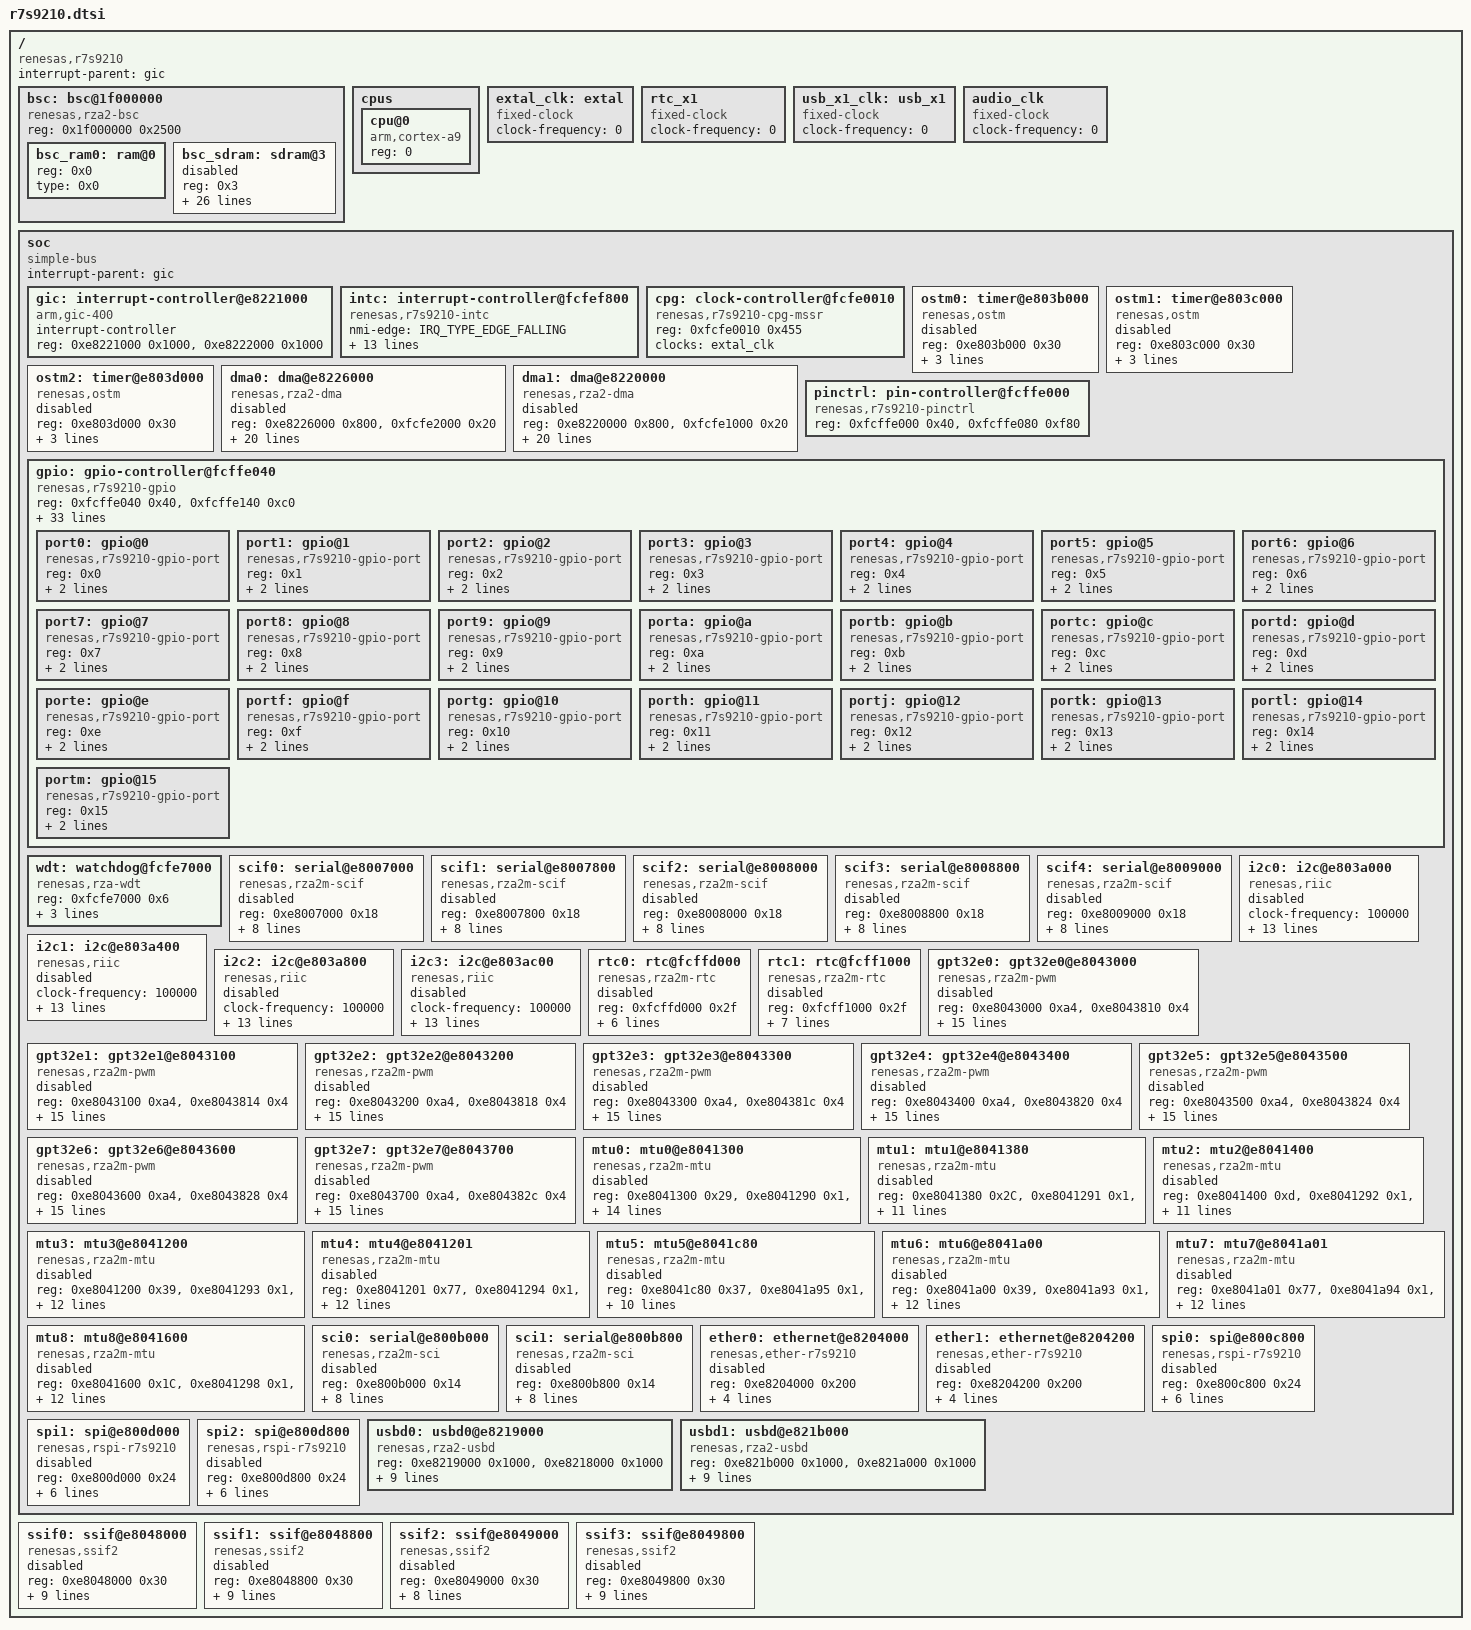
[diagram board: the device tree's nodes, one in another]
/*
 * Copyright (c) 2023 EPAM Systems
 *
 * SPDX-License-Identifier: Apache-2.0
 */

#include <mem.h>
#include <arm/armv7-a.dtsi>
#include <zephyr/dt-bindings/gpio/rza2-gpio.h>
#include <zephyr/dt-bindings/interrupt-controller/arm-gic.h>
#include <zephyr/dt-bindings/interrupt-controller/r7s9210-intc.h>
#include <zephyr/dt-bindings/clock/renesas_cpg_mssr.h>
#include <zephyr/dt-bindings/clock/r7s9210_cpg_mssr.h>
#include <zephyr/dt-bindings/dma/rza2_dma.h>
#include <zephyr/dt-bindings/pwm/pwm.h>
#include <zephyr/dt-bindings/pwm/rza2m_pwm.h>

/ {
	compatible = "renesas,r7s9210";
	interrupt-parent = <&gic>;
	#address-cells = <1>;
	#size-cells = <1>;

	bsc: bsc@1f000000 {
		compatible = "renesas,rza2-bsc";
		reg = <0x1f000000 0x2500>;
		#address-cells = <1>;
		#size-cells = <0>;

		bsc_ram0: ram@0 {
			reg = <0x0>;
			type = <0x0>; /* Normal mem */
		};

		/* Enable this node if SDRAM is connected */
		bsc_sdram: sdram@3 {
			reg = <0x3>;
			type = <0x4>; /* SDRAM */
			bsz = <16>;
			wtrp = <1>;
			wtrcd = <3>;
			a3cl = <3>;
			trwl = <2>;
			wtrc = <8>;
			auto_ref = <1>;
			bactv = <0>;
			a3row = <0x2>; /* 13 bit */
			a3col = <0x2>; /* 10 bit */
			a2row = <0x2>; /* 13 bit */
			a2col = <0x2>; /* 10 bit */
			cks = <2>; /* CKIO/16 */
			rrc = <1>;
			rtcor = <0x40>;
			sdrodly = <0x2>;
			sdridly = <0xf>;
			iwrrd = <0x0>;
			iwrrs = <0x0>;
			iww = <0x0>;
			iwrwd = <0x0>;
			iwrws = <0x0>;
			idle = <0x33F1>;
			sdcs2 = <0x0>;
			sdcs3 = <0x0>;
			status = "disabled";
		};
	};

	cpus {
		#address-cells = <1>;
		#size-cells = <0>;

		cpu@0 {
			device_type = "cpu";
			compatible = "arm,cortex-a9";
			reg = <0>;
		};
	};

	extal_clk: extal {
		#clock-cells = <0>;
		compatible = "fixed-clock";
		/* Value must be set by board */
		clock-frequency = <0>;
	};

	rtc_x1: rtc_x1 {
		#clock-cells = <0>;
		compatible = "fixed-clock";
		/* value must be set by board */
		clock-frequency = <0>;
	};

	usb_x1_clk: usb_x1 {
		#clock-cells = <0>;
		compatible = "fixed-clock";
		/* If clk present, value (48000000) must be set by board */
		clock-frequency = <0>;
	};

	audio_clk: audio_clk {
		#clock-cells = <0>;
		compatible = "fixed-clock";
		/* value must be set by board */
		clock-frequency = <0>;
	};

	soc {
		compatible = "simple-bus";
		interrupt-parent = <&gic>;

		#address-cells = <1>;
		#size-cells = <1>;
		ranges;

		gic: interrupt-controller@e8221000 {
			compatible = "arm,gic-400", "arm,gic-v2", "arm,gic";
			#interrupt-cells = <4>;
			#address-cells = <0>;
			interrupt-controller;
			reg = <0xe8221000 0x1000>,
			      <0xe8222000 0x1000>;
		};

		intc: interrupt-controller@fcfef800 {
			compatible = "renesas,r7s9210-intc";
			#interrupt-cells = <2>;
			#address-cells = <0>;
			nmi-edge = <IRQ_TYPE_EDGE_FALLING>;
			interrupts =
				<GIC_SPI 4  IRQ_TYPE_LEVEL IRQ_DEFAULT_PRIORITY>,
				<GIC_SPI 5  IRQ_TYPE_LEVEL IRQ_DEFAULT_PRIORITY>,
				<GIC_SPI 6  IRQ_TYPE_LEVEL IRQ_DEFAULT_PRIORITY>,
				<GIC_SPI 7  IRQ_TYPE_LEVEL IRQ_DEFAULT_PRIORITY>,
				<GIC_SPI 8  IRQ_TYPE_LEVEL IRQ_DEFAULT_PRIORITY>,
				<GIC_SPI 9  IRQ_TYPE_LEVEL IRQ_DEFAULT_PRIORITY>,
				<GIC_SPI 10 IRQ_TYPE_LEVEL IRQ_DEFAULT_PRIORITY>,
				<GIC_SPI 11 IRQ_TYPE_LEVEL IRQ_DEFAULT_PRIORITY>;
			map = <0 1 2 3 4 5 6 7>;
			interrupt-controller;
			interrupt-parent = <&gic>;
			reg = <0xfcfef800 0x6>;
		};

		cpg: clock-controller@fcfe0010 {
			compatible = "renesas,r7s9210-cpg-mssr";
			reg = <0xfcfe0010 0x455>;
			#clock-cells = <2>;
			clocks = <&extal_clk>;
		};

		/* By default, this timer can only be accessed from security mode. If you wish to
		 * enable access to it from non-secure mode, you will need to modify the SLVACCCTL1
		 * AXI register.
		 * See, RZ/A2M Group User’s Manual: Hardware (R01UH0746EJ0400 Rev.4.00)
		 * 5.11.26 Slave Access Control Register 1 (SLVACCCTL1)
		 */
		ostm0: timer@e803b000 {
			compatible = "renesas,ostm";
			reg = <0xe803b000 0x30>;
			interrupts = <GIC_SPI 56 IRQ_TYPE_LEVEL IRQ_DEFAULT_PRIORITY>;
			clocks = <&cpg CPG_MOD 36>;
			status = "disabled";
		};

		ostm1: timer@e803c000 {
			compatible = "renesas,ostm";
			reg = <0xe803c000 0x30>;
			interrupts = <GIC_SPI 57 IRQ_TYPE_EDGE IRQ_DEFAULT_PRIORITY>;
			clocks = <&cpg CPG_MOD 35>;
			status = "disabled";
		};

		ostm2: timer@e803d000 {
			compatible = "renesas,ostm";
			reg = <0xe803d000 0x30>;
			interrupts = <GIC_SPI 58 IRQ_TYPE_EDGE IRQ_DEFAULT_PRIORITY>;
			clocks = <&cpg CPG_MOD 34>;
			status = "disabled";
		};

		dma0: dma@e8226000 { /* Non Secure DMA */
			compatible = "renesas,rza2-dma";
			reg = <0xe8226000 0x800>, <0xfcfe2000 0x20>;
			reg-names = "reg_main", "ext";
			interrupts = <GIC_SPI 302 IRQ_TYPE_EDGE IRQ_DEFAULT_PRIORITY>,
				     <GIC_SPI 303 IRQ_TYPE_EDGE IRQ_DEFAULT_PRIORITY>,
				     <GIC_SPI 304 IRQ_TYPE_EDGE IRQ_DEFAULT_PRIORITY>,
				     <GIC_SPI 305 IRQ_TYPE_EDGE IRQ_DEFAULT_PRIORITY>,
				     <GIC_SPI 306 IRQ_TYPE_EDGE IRQ_DEFAULT_PRIORITY>,
				     <GIC_SPI 307 IRQ_TYPE_EDGE IRQ_DEFAULT_PRIORITY>,
				     <GIC_SPI 308 IRQ_TYPE_EDGE IRQ_DEFAULT_PRIORITY>,
				     <GIC_SPI 309 IRQ_TYPE_EDGE IRQ_DEFAULT_PRIORITY>,
				     <GIC_SPI 310 IRQ_TYPE_EDGE IRQ_DEFAULT_PRIORITY>,
				     <GIC_SPI 311 IRQ_TYPE_EDGE IRQ_DEFAULT_PRIORITY>,
				     <GIC_SPI 358 IRQ_TYPE_EDGE IRQ_DEFAULT_PRIORITY>,
				     <GIC_SPI 359 IRQ_TYPE_EDGE IRQ_DEFAULT_PRIORITY>,
				     <GIC_SPI 360 IRQ_TYPE_EDGE IRQ_DEFAULT_PRIORITY>,
				     <GIC_SPI 361 IRQ_TYPE_EDGE IRQ_DEFAULT_PRIORITY>,
				     <GIC_SPI 362 IRQ_TYPE_EDGE IRQ_DEFAULT_PRIORITY>,
				     <GIC_SPI 363 IRQ_TYPE_EDGE IRQ_DEFAULT_PRIORITY>,
				     <GIC_SPI 30 IRQ_TYPE_EDGE IRQ_DEFAULT_PRIORITY>; /* DMAERR1 */
			interrupt-names = "ch0", "ch1", "ch2", "ch3",
					"ch4", "ch5", "ch6", "ch7",
					"ch8", "ch9", "ch10", "ch11",
					"ch12", "ch13", "ch14", "ch15",
					"err1";
			dma-channels = <16>;
			#dma-cells = <3>;
			dma-buf-addr-alignment = <4>;
			status = "disabled";
		};

		dma1: dma@e8220000 { /* Secure DMA */
			compatible = "renesas,rza2-dma";
			reg = <0xe8220000 0x800>, <0xfcfe1000 0x20>;
			reg-names = "reg_main", "ext";
			interrupts = <GIC_SPI 13 IRQ_TYPE_EDGE IRQ_DEFAULT_PRIORITY>,
				     <GIC_SPI 14 IRQ_TYPE_EDGE IRQ_DEFAULT_PRIORITY>,
				     <GIC_SPI 15 IRQ_TYPE_EDGE IRQ_DEFAULT_PRIORITY>,
				     <GIC_SPI 16 IRQ_TYPE_EDGE IRQ_DEFAULT_PRIORITY>,
				     <GIC_SPI 17 IRQ_TYPE_EDGE IRQ_DEFAULT_PRIORITY>,
				     <GIC_SPI 18 IRQ_TYPE_EDGE IRQ_DEFAULT_PRIORITY>,
				     <GIC_SPI 19 IRQ_TYPE_EDGE IRQ_DEFAULT_PRIORITY>,
				     <GIC_SPI 20 IRQ_TYPE_EDGE IRQ_DEFAULT_PRIORITY>,
				     <GIC_SPI 21 IRQ_TYPE_EDGE IRQ_DEFAULT_PRIORITY>,
				     <GIC_SPI 22 IRQ_TYPE_EDGE IRQ_DEFAULT_PRIORITY>,
				     <GIC_SPI 23 IRQ_TYPE_EDGE IRQ_DEFAULT_PRIORITY>,
				     <GIC_SPI 24 IRQ_TYPE_EDGE IRQ_DEFAULT_PRIORITY>,
				     <GIC_SPI 25 IRQ_TYPE_EDGE IRQ_DEFAULT_PRIORITY>,
				     <GIC_SPI 26 IRQ_TYPE_EDGE IRQ_DEFAULT_PRIORITY>,
				     <GIC_SPI 27 IRQ_TYPE_EDGE IRQ_DEFAULT_PRIORITY>,
				     <GIC_SPI 28 IRQ_TYPE_EDGE IRQ_DEFAULT_PRIORITY>,
				     <GIC_SPI 29 IRQ_TYPE_EDGE IRQ_DEFAULT_PRIORITY>; /* DMAERR0 */
			interrupt-names = "ch0", "ch1", "ch2", "ch3",
					"ch4", "ch5", "ch6", "ch7",
					"ch8", "ch9", "ch10", "ch11",
					"ch12", "ch13", "ch14", "ch15",
					"err0";
			dma-channels = <16>;
			#dma-cells = <3>;
			dma-buf-addr-alignment = <4>;
			status = "disabled";
		};

		pinctrl: pin-controller@fcffe000 {
			compatible = "renesas,r7s9210-pinctrl";
			reg = <0xfcffe000 0x40>, <0xfcffe080 0xf80>;
			reg-names = "pdr", "pinctrl";
		};

		gpio: gpio-controller@fcffe040{
			compatible = "renesas,r7s9210-gpio";
			reg = <0xfcffe040 0x40>, <0xfcffe140 0xc0>;
			reg-names = "io", "dscr";
			#address-cells = <1>;
			#size-cells = <0>;

			interrupts = <GIC_SPI 479 IRQ_TYPE_EDGE IRQ_DEFAULT_PRIORITY>, /* TINT31 */
				     <GIC_SPI 478 IRQ_TYPE_EDGE IRQ_DEFAULT_PRIORITY>, /* TINT30 */
				     <GIC_SPI 477 IRQ_TYPE_EDGE IRQ_DEFAULT_PRIORITY>, /* TINT29 */
				     <GIC_SPI 476 IRQ_TYPE_EDGE IRQ_DEFAULT_PRIORITY>, /* TINT28 */
				     <GIC_SPI 475 IRQ_TYPE_EDGE IRQ_DEFAULT_PRIORITY>, /* TINT27 */
				     <GIC_SPI 474 IRQ_TYPE_EDGE IRQ_DEFAULT_PRIORITY>, /* TINT26 */
				     <GIC_SPI 473 IRQ_TYPE_EDGE IRQ_DEFAULT_PRIORITY>, /* TINT25 */
				     <GIC_SPI 472 IRQ_TYPE_EDGE IRQ_DEFAULT_PRIORITY>, /* TINT24 */
				     <GIC_SPI 471 IRQ_TYPE_EDGE IRQ_DEFAULT_PRIORITY>, /* TINT23 */
				     <GIC_SPI 470 IRQ_TYPE_EDGE IRQ_DEFAULT_PRIORITY>, /* TINT22 */
				     <GIC_SPI 469 IRQ_TYPE_EDGE IRQ_DEFAULT_PRIORITY>, /* TINT21 */
				     <GIC_SPI 468 IRQ_TYPE_EDGE IRQ_DEFAULT_PRIORITY>, /* TINT20 */
				     <GIC_SPI 467 IRQ_TYPE_EDGE IRQ_DEFAULT_PRIORITY>, /* TINT19 */
				     <GIC_SPI 466 IRQ_TYPE_EDGE IRQ_DEFAULT_PRIORITY>, /* TINT18 */
				     <GIC_SPI 465 IRQ_TYPE_EDGE IRQ_DEFAULT_PRIORITY>, /* TINT17 */
				     <GIC_SPI 464 IRQ_TYPE_EDGE IRQ_DEFAULT_PRIORITY>, /* TINT16 */
				     <GIC_SPI 463 IRQ_TYPE_EDGE IRQ_DEFAULT_PRIORITY>, /* TINT15 */
				     <GIC_SPI 462 IRQ_TYPE_EDGE IRQ_DEFAULT_PRIORITY>, /* TINT14 */
				     <GIC_SPI 461 IRQ_TYPE_EDGE IRQ_DEFAULT_PRIORITY>, /* TINT13 */
				     <GIC_SPI 460 IRQ_TYPE_EDGE IRQ_DEFAULT_PRIORITY>, /* TINT12 */
				     <GIC_SPI 459 IRQ_TYPE_EDGE IRQ_DEFAULT_PRIORITY>, /* TINT11 */
				     <GIC_SPI 458 IRQ_TYPE_EDGE IRQ_DEFAULT_PRIORITY>, /* TINT10 */
				     <GIC_SPI 457 IRQ_TYPE_EDGE IRQ_DEFAULT_PRIORITY>, /* TINT9 */
				     <GIC_SPI 456 IRQ_TYPE_EDGE IRQ_DEFAULT_PRIORITY>, /* TINT8 */
				     <GIC_SPI 455 IRQ_TYPE_EDGE IRQ_DEFAULT_PRIORITY>, /* TINT7 */
				     <GIC_SPI 454 IRQ_TYPE_EDGE IRQ_DEFAULT_PRIORITY>, /* TINT6 */
				     <GIC_SPI 453 IRQ_TYPE_EDGE IRQ_DEFAULT_PRIORITY>, /* TINT5 */
				     <GIC_SPI 452 IRQ_TYPE_EDGE IRQ_DEFAULT_PRIORITY>, /* TINT4 */
				     <GIC_SPI 451 IRQ_TYPE_EDGE IRQ_DEFAULT_PRIORITY>, /* TINT3 */
				     <GIC_SPI 450 IRQ_TYPE_EDGE IRQ_DEFAULT_PRIORITY>, /* TINT2 */
				     <GIC_SPI 449 IRQ_TYPE_EDGE IRQ_DEFAULT_PRIORITY>, /* TINT1 */
				     <GIC_SPI 448 IRQ_TYPE_EDGE IRQ_DEFAULT_PRIORITY>; /* TINT0 */

			port0: gpio@0 {
				compatible = "renesas,r7s9210-gpio-port";
				reg = <0x0>; /* PORT0 */
				gpio-controller;
				#gpio-cells=<2>;
				ngpios = <8>;
			};

			port1: gpio@1 {
				compatible = "renesas,r7s9210-gpio-port";
				reg = <0x1>; /* PORT1 */
				gpio-controller;
				#gpio-cells=<2>;
				ngpios = <8>;
			};
			port2: gpio@2 {
				compatible = "renesas,r7s9210-gpio-port";
				reg = <0x2>; /* PORT2 */
				gpio-controller;
				#gpio-cells=<2>;
				ngpios = <8>;
			};
			port3: gpio@3 {
				compatible = "renesas,r7s9210-gpio-port";
				reg = <0x3>; /* PORT3 */
				gpio-controller;
				#gpio-cells=<2>;
				ngpios = <8>;
			};
			port4: gpio@4 {
				compatible = "renesas,r7s9210-gpio-port";
				reg = <0x4>; /* PORT4 */
				gpio-controller;
				#gpio-cells=<2>;
				ngpios = <8>;
			};
			port5: gpio@5 {
				compatible = "renesas,r7s9210-gpio-port";
				reg = <0x5>; /* PORT5 */
				gpio-controller;
				#gpio-cells=<2>;
				ngpios = <8>;
			};
			port6: gpio@6 {
				compatible = "renesas,r7s9210-gpio-port";
				reg = <0x6>; /* PORT6 */
				gpio-controller;
				#gpio-cells=<2>;
				ngpios = <8>;
			};
			port7: gpio@7 {
				compatible = "renesas,r7s9210-gpio-port";
				reg = <0x7>; /* PORT7 */
				gpio-controller;
				#gpio-cells=<2>;
				ngpios = <8>;
			};
			port8: gpio@8 {
				compatible = "renesas,r7s9210-gpio-port";
				reg = <0x8>; /* PORT8 */
				gpio-controller;
				#gpio-cells=<2>;
				ngpios = <8>;
			};
			port9: gpio@9 {
				compatible = "renesas,r7s9210-gpio-port";
				reg = <0x9>; /* PORT9 */
				gpio-controller;
				#gpio-cells=<2>;
				ngpios = <8>;
			};
			porta: gpio@a {
				compatible = "renesas,r7s9210-gpio-port";
				reg = <0xa>; /* PORTA */
				gpio-controller;
				#gpio-cells=<2>;
				ngpios = <8>;
			};
			portb: gpio@b {
				compatible = "renesas,r7s9210-gpio-port";
				reg = <0xb>; /* PORTB */
				gpio-controller;
				#gpio-cells=<2>;
				ngpios = <8>;
			};
			portc: gpio@c {
				compatible = "renesas,r7s9210-gpio-port";
				reg = <0xc>; /* PORTC */
				gpio-controller;
				#gpio-cells=<2>;
				ngpios = <8>;
			};
			portd: gpio@d {
				compatible = "renesas,r7s9210-gpio-port";
				reg = <0xd>; /* PORTD */
				gpio-controller;
				#gpio-cells=<2>;
				ngpios = <8>;
			};
			porte: gpio@e {
				compatible = "renesas,r7s9210-gpio-port";
				reg = <0xe>; /* PORTE */
				gpio-controller;
				#gpio-cells=<2>;
				ngpios = <8>;
			};
			portf: gpio@f {
				compatible = "renesas,r7s9210-gpio-port";
				reg = <0xf>; /* PORTF */
				gpio-controller;
				#gpio-cells=<2>;
				ngpios = <8>;
			};
			portg: gpio@10 {
				compatible = "renesas,r7s9210-gpio-port";
				reg = <0x10>; /* PORTG */
				gpio-controller;
				#gpio-cells=<2>;
				ngpios = <8>;
			};
			porth: gpio@11 {
				compatible = "renesas,r7s9210-gpio-port";
				reg = <0x11>; /* PORTH */
				gpio-controller;
				#gpio-cells=<2>;
				ngpios = <8>;
			};
			portj: gpio@12 {
				compatible = "renesas,r7s9210-gpio-port";
				reg = <0x12>; /* PORTJ */
				gpio-controller;
				#gpio-cells=<2>;
				ngpios = <8>;
			};
			portk: gpio@13 {
				compatible = "renesas,r7s9210-gpio-port";
				reg = <0x13>; /* PORTK */
				gpio-controller;
				#gpio-cells=<2>;
				ngpios = <8>;
			};
			portl: gpio@14 {
				compatible = "renesas,r7s9210-gpio-port";
				reg = <0x14>; /* PORTL */
				gpio-controller;
				#gpio-cells=<2>;
				ngpios = <8>;
			};
			portm: gpio@15 {
				compatible = "renesas,r7s9210-gpio-port";
				reg = <0x15>; /* PORTM */
				gpio-controller;
				#gpio-cells=<2>;
				ngpios = <8>;
			};
		};

		wdt: watchdog@fcfe7000 {
			compatible = "renesas,rza-wdt";
			reg = <0xfcfe7000 0x6>;
			/* interval timer interrupt is generated only in interval timer mode */
			interrupts = <GIC_SPI 61 IRQ_TYPE_LEVEL IRQ_DEFAULT_PRIORITY>;
			clocks = <&cpg CPG_CORE R7S9210_CLK_P0>;
		};

		scif0: serial@e8007000 {
			compatible = "renesas,rza2m-scif";
			reg = <0xe8007000 0x18>;
			interrupt-parent = <&gic>;
			interrupts = <GIC_SPI 265 IRQ_TYPE_LEVEL IRQ_DEFAULT_PRIORITY>,
				     <GIC_SPI 266 IRQ_TYPE_LEVEL IRQ_DEFAULT_PRIORITY>,
				     <GIC_SPI 267 IRQ_TYPE_LEVEL IRQ_DEFAULT_PRIORITY>,
				     <GIC_SPI 268 IRQ_TYPE_LEVEL IRQ_DEFAULT_PRIORITY>;
			interrupt-names = "eri", "rxi", "txi", "tei";
			clocks = <&cpg CPG_MOD 47>, <&cpg CPG_CORE R7S9210_CLK_P1C>;
			clock-names = "fck", "bus";
			status = "disabled";
		};

		scif1: serial@e8007800 {
			compatible = "renesas,rza2m-scif";
			reg = <0xe8007800 0x18>;
			interrupt-parent = <&gic>;
			interrupts = <GIC_SPI 271 IRQ_TYPE_LEVEL IRQ_DEFAULT_PRIORITY>,
				     <GIC_SPI 272 IRQ_TYPE_LEVEL IRQ_DEFAULT_PRIORITY>,
				     <GIC_SPI 273 IRQ_TYPE_LEVEL IRQ_DEFAULT_PRIORITY>,
				     <GIC_SPI 274 IRQ_TYPE_LEVEL IRQ_DEFAULT_PRIORITY>;
			interrupt-names = "eri", "rxi", "txi", "tei";
			clocks = <&cpg CPG_MOD 46>, <&cpg CPG_CORE R7S9210_CLK_P1C>;
			clock-names = "fck", "bus";
			status = "disabled";
		};

		scif2: serial@e8008000 {
			compatible = "renesas,rza2m-scif";
			reg = <0xe8008000 0x18>;
			interrupt-parent = <&gic>;
			interrupts = <GIC_SPI 277 IRQ_TYPE_LEVEL IRQ_DEFAULT_PRIORITY>,
				     <GIC_SPI 278 IRQ_TYPE_LEVEL IRQ_DEFAULT_PRIORITY>,
				     <GIC_SPI 279 IRQ_TYPE_LEVEL IRQ_DEFAULT_PRIORITY>,
				     <GIC_SPI 280 IRQ_TYPE_LEVEL IRQ_DEFAULT_PRIORITY>;
			interrupt-names = "eri", "rxi", "txi", "tei";
			clocks = <&cpg CPG_MOD 45>, <&cpg CPG_CORE R7S9210_CLK_P1C>;
			clock-names = "fck", "bus";
			status = "disabled";
		};

		scif3: serial@e8008800 {
			compatible = "renesas,rza2m-scif";
			reg = <0xe8008800 0x18>;
			interrupt-parent = <&gic>;
			interrupts = <GIC_SPI 283 IRQ_TYPE_LEVEL IRQ_DEFAULT_PRIORITY>,
				     <GIC_SPI 284 IRQ_TYPE_LEVEL IRQ_DEFAULT_PRIORITY>,
				     <GIC_SPI 285 IRQ_TYPE_LEVEL IRQ_DEFAULT_PRIORITY>,
				     <GIC_SPI 286 IRQ_TYPE_LEVEL IRQ_DEFAULT_PRIORITY>;
			interrupt-names = "eri", "rxi", "txi", "tei";
			clocks = <&cpg CPG_MOD 44>, <&cpg CPG_CORE R7S9210_CLK_P1C>;
			clock-names = "fck", "bus";
			status = "disabled";
		};

		scif4: serial@e8009000 {
			compatible = "renesas,rza2m-scif";
			reg = <0xe8009000 0x18>;
			interrupt-parent = <&gic>;
			interrupts = <GIC_SPI 289 IRQ_TYPE_LEVEL IRQ_DEFAULT_PRIORITY>,
				     <GIC_SPI 290 IRQ_TYPE_LEVEL IRQ_DEFAULT_PRIORITY>,
				     <GIC_SPI 291 IRQ_TYPE_LEVEL IRQ_DEFAULT_PRIORITY>,
				     <GIC_SPI 292 IRQ_TYPE_LEVEL IRQ_DEFAULT_PRIORITY>;
			interrupt-names = "eri", "rxi", "txi", "tei";
			clocks = <&cpg CPG_MOD 43>, <&cpg CPG_CORE R7S9210_CLK_P1C>;
			clock-names = "fck", "bus";
			status = "disabled";
		};

		i2c0: i2c@e803a000 {
			compatible = "renesas,riic";
			clock-frequency = <100000>;
			#address-cells = <1>;
			#size-cells = <0>;
			reg = <0xe803a000 0x50>;
			interrupt-parent = <&gic>;
			interrupts = <GIC_SPI 232 IRQ_TYPE_LEVEL IRQ_DEFAULT_PRIORITY>,
				     <GIC_SPI 233 IRQ_TYPE_EDGE IRQ_DEFAULT_PRIORITY>,
				     <GIC_SPI 234 IRQ_TYPE_EDGE IRQ_DEFAULT_PRIORITY>,
				     <GIC_SPI 235 IRQ_TYPE_LEVEL IRQ_DEFAULT_PRIORITY>,
				     <GIC_SPI 236 IRQ_TYPE_LEVEL IRQ_DEFAULT_PRIORITY>,
				     <GIC_SPI 237 IRQ_TYPE_LEVEL IRQ_DEFAULT_PRIORITY>,
				     <GIC_SPI 238 IRQ_TYPE_LEVEL IRQ_DEFAULT_PRIORITY>,
				     <GIC_SPI 239 IRQ_TYPE_LEVEL IRQ_DEFAULT_PRIORITY>;
			interrupt-names = "tei", "ri", "ti", "spi",
					  "sti", "nacki", "ali", "tmoi";
			clocks = <&cpg CPG_MOD 87>, <&cpg CPG_CORE R7S9210_CLK_P1>;
			status = "disabled";
		};
		i2c1: i2c@e803a400 {
			compatible = "renesas,riic";
			clock-frequency = <100000>;
			#address-cells = <1>;
			#size-cells = <0>;
			reg = <0xe803a400 0x50>;
			interrupt-parent = <&gic>;
			interrupts = <GIC_SPI 240 IRQ_TYPE_LEVEL IRQ_DEFAULT_PRIORITY>,
				     <GIC_SPI 241 IRQ_TYPE_EDGE IRQ_DEFAULT_PRIORITY>,
				     <GIC_SPI 242 IRQ_TYPE_EDGE IRQ_DEFAULT_PRIORITY>,
				     <GIC_SPI 243 IRQ_TYPE_LEVEL IRQ_DEFAULT_PRIORITY>,
				     <GIC_SPI 244 IRQ_TYPE_LEVEL IRQ_DEFAULT_PRIORITY>,
				     <GIC_SPI 245 IRQ_TYPE_LEVEL IRQ_DEFAULT_PRIORITY>,
				     <GIC_SPI 246 IRQ_TYPE_LEVEL IRQ_DEFAULT_PRIORITY>,
				     <GIC_SPI 247 IRQ_TYPE_LEVEL IRQ_DEFAULT_PRIORITY>;
			interrupt-names = "tei", "ri", "ti", "spi",
					  "sti", "nacki", "ali", "tmoi";
			clocks = <&cpg CPG_MOD 86>, <&cpg CPG_CORE R7S9210_CLK_P1>;
			status = "disabled";
		};
		i2c2: i2c@e803a800 {
			compatible = "renesas,riic";
			clock-frequency = <100000>;
			#address-cells = <1>;
			#size-cells = <0>;
			reg = <0xe803a800 0x50>;
			interrupt-parent = <&gic>;
			interrupts = <GIC_SPI 248 IRQ_TYPE_LEVEL IRQ_DEFAULT_PRIORITY>,
				     <GIC_SPI 249 IRQ_TYPE_EDGE IRQ_DEFAULT_PRIORITY>,
				     <GIC_SPI 250 IRQ_TYPE_EDGE IRQ_DEFAULT_PRIORITY>,
				     <GIC_SPI 251 IRQ_TYPE_LEVEL IRQ_DEFAULT_PRIORITY>,
				     <GIC_SPI 252 IRQ_TYPE_LEVEL IRQ_DEFAULT_PRIORITY>,
				     <GIC_SPI 253 IRQ_TYPE_LEVEL IRQ_DEFAULT_PRIORITY>,
				     <GIC_SPI 254 IRQ_TYPE_LEVEL IRQ_DEFAULT_PRIORITY>,
				     <GIC_SPI 255 IRQ_TYPE_LEVEL IRQ_DEFAULT_PRIORITY>;
			interrupt-names = "tei", "ri", "ti", "spi",
					  "sti", "nacki", "ali", "tmoi";
			clocks = <&cpg CPG_MOD 85>, <&cpg CPG_CORE R7S9210_CLK_P1>;
			status = "disabled";
		};
		i2c3: i2c@e803ac00 {
			compatible = "renesas,riic";
			clock-frequency = <100000>;
			#address-cells = <1>;
			#size-cells = <0>;
			reg = <0xe803ac00 0x50>;
			interrupt-parent = <&gic>;
			interrupts = <GIC_SPI 256 IRQ_TYPE_LEVEL IRQ_DEFAULT_PRIORITY>,
				     <GIC_SPI 257 IRQ_TYPE_EDGE IRQ_DEFAULT_PRIORITY>,
				     <GIC_SPI 258 IRQ_TYPE_EDGE IRQ_DEFAULT_PRIORITY>,
				     <GIC_SPI 259 IRQ_TYPE_LEVEL IRQ_DEFAULT_PRIORITY>,
				     <GIC_SPI 260 IRQ_TYPE_LEVEL IRQ_DEFAULT_PRIORITY>,
				     <GIC_SPI 261 IRQ_TYPE_LEVEL IRQ_DEFAULT_PRIORITY>,
				     <GIC_SPI 262 IRQ_TYPE_LEVEL IRQ_DEFAULT_PRIORITY>,
				     <GIC_SPI 263 IRQ_TYPE_LEVEL IRQ_DEFAULT_PRIORITY>;
			interrupt-names = "tei", "ri", "ti", "spi",
					  "sti", "nacki", "ali", "tmoi";
			clocks = <&cpg CPG_MOD 84>, <&cpg CPG_CORE R7S9210_CLK_P1>;
			status = "disabled";
		};

		/* secure channel */
		rtc0: rtc@fcffd000 {
			compatible = "renesas,rza2m-rtc";
			reg = <0xfcffd000 0x2f>;
			interrupts = <GIC_SPI 327 IRQ_TYPE_EDGE IRQ_DEFAULT_PRIORITY>,
				     <GIC_SPI 328 IRQ_TYPE_EDGE IRQ_DEFAULT_PRIORITY>,
				     <GIC_SPI 329 IRQ_TYPE_EDGE IRQ_DEFAULT_PRIORITY>;
			interrupt-names = "alarm", "period", "carry";
			clocks = <&cpg CPG_MOD 53>;
			alarms-count = <1>;
			status = "disabled";
		};

		/* non-secure channel */
		rtc1: rtc@fcff1000 {
			compatible = "renesas,rza2m-rtc";
			reg = <0xfcff1000 0x2f>;
			interrupts = <GIC_SPI 330 IRQ_TYPE_EDGE IRQ_DEFAULT_PRIORITY>,
				     <GIC_SPI 331 IRQ_TYPE_EDGE IRQ_DEFAULT_PRIORITY>,
				     <GIC_SPI 332 IRQ_TYPE_EDGE IRQ_DEFAULT_PRIORITY>;
			interrupt-names = "alarm", "period", "carry";
			interrupt-parent = <&gic>;
			clocks = <&cpg CPG_MOD 52>;
			alarms-count = <1>;
			status = "disabled";
		};

		/* General Purpose PWM Timer Channels */
		gpt32e0: gpt32e0@e8043000 {
			compatible = "renesas,rza2m-pwm";
			reg = <0xe8043000 0xa4>, <0xe8043810 0x4>;
			reg-names = "GPT32E", "GTESR";
			interrupts = <GIC_SPI 107 IRQ_TYPE_EDGE IRQ_DEFAULT_PRIORITY>,
				     <GIC_SPI 108 IRQ_TYPE_EDGE IRQ_DEFAULT_PRIORITY>,
				     <GIC_SPI 109 IRQ_TYPE_EDGE IRQ_DEFAULT_PRIORITY>,
				     <GIC_SPI 110 IRQ_TYPE_EDGE IRQ_DEFAULT_PRIORITY>,
				     <GIC_SPI 114 IRQ_TYPE_EDGE IRQ_DEFAULT_PRIORITY>,
				     <GIC_SPI 115 IRQ_TYPE_EDGE IRQ_DEFAULT_PRIORITY>,
				     <GIC_SPI 116 IRQ_TYPE_EDGE IRQ_DEFAULT_PRIORITY>,
				     <GIC_SPI 117 IRQ_TYPE_EDGE IRQ_DEFAULT_PRIORITY>,
				     <GIC_SPI 118 IRQ_TYPE_EDGE IRQ_DEFAULT_PRIORITY>,
				     <GIC_SPI 119 IRQ_TYPE_EDGE IRQ_DEFAULT_PRIORITY>;
			interrupt-names = "ccmpa", "ccmpb", "cmpc", "cmpd", "cmpe", "cmpf",
					  "adtrga", "adtrgb", "ovf", "unf";
			interrupt-parent = <&gic>;
			clocks = <&cpg CPG_MOD 30>, <&cpg CPG_CORE R7S9210_CLK_P1C>;
			#pwm-cells = <3>;
			channel-id = <0>;
			status = "disabled";
		};

		gpt32e1: gpt32e1@e8043100 {
			compatible = "renesas,rza2m-pwm";
			reg = <0xe8043100 0xa4>, <0xe8043814 0x4>;
			reg-names = "GPT32E", "GTESR";
			interrupts = <GIC_SPI 120 IRQ_TYPE_EDGE IRQ_DEFAULT_PRIORITY>,
				     <GIC_SPI 121 IRQ_TYPE_EDGE IRQ_DEFAULT_PRIORITY>,
				     <GIC_SPI 122 IRQ_TYPE_EDGE IRQ_DEFAULT_PRIORITY>,
				     <GIC_SPI 123 IRQ_TYPE_EDGE IRQ_DEFAULT_PRIORITY>,
				     <GIC_SPI 127 IRQ_TYPE_EDGE IRQ_DEFAULT_PRIORITY>,
				     <GIC_SPI 128 IRQ_TYPE_EDGE IRQ_DEFAULT_PRIORITY>,
				     <GIC_SPI 129 IRQ_TYPE_EDGE IRQ_DEFAULT_PRIORITY>,
				     <GIC_SPI 130 IRQ_TYPE_EDGE IRQ_DEFAULT_PRIORITY>,
				     <GIC_SPI 131 IRQ_TYPE_EDGE IRQ_DEFAULT_PRIORITY>,
				     <GIC_SPI 132 IRQ_TYPE_EDGE IRQ_DEFAULT_PRIORITY>;
			interrupt-names = "ccmpa", "ccmpb", "cmpc", "cmpd", "cmpe", "cmpf",
					  "adtrga", "adtrgb", "ovf", "unf";
			interrupt-parent = <&gic>;
			clocks = <&cpg CPG_MOD 30>, <&cpg CPG_CORE R7S9210_CLK_P1C>;
			#pwm-cells = <3>;
			channel-id = <1>;
			status = "disabled";
		};

		gpt32e2: gpt32e2@e8043200 {
			compatible = "renesas,rza2m-pwm";
			reg = <0xe8043200 0xa4>, <0xe8043818 0x4>;
			reg-names = "GPT32E", "GTESR";
			interrupts = <GIC_SPI 133 IRQ_TYPE_EDGE IRQ_DEFAULT_PRIORITY>,
				     <GIC_SPI 134 IRQ_TYPE_EDGE IRQ_DEFAULT_PRIORITY>,
				     <GIC_SPI 135 IRQ_TYPE_EDGE IRQ_DEFAULT_PRIORITY>,
				     <GIC_SPI 136 IRQ_TYPE_EDGE IRQ_DEFAULT_PRIORITY>,
				     <GIC_SPI 140 IRQ_TYPE_EDGE IRQ_DEFAULT_PRIORITY>,
				     <GIC_SPI 141 IRQ_TYPE_EDGE IRQ_DEFAULT_PRIORITY>,
				     <GIC_SPI 142 IRQ_TYPE_EDGE IRQ_DEFAULT_PRIORITY>,
				     <GIC_SPI 143 IRQ_TYPE_EDGE IRQ_DEFAULT_PRIORITY>,
				     <GIC_SPI 144 IRQ_TYPE_EDGE IRQ_DEFAULT_PRIORITY>,
				     <GIC_SPI 145 IRQ_TYPE_EDGE IRQ_DEFAULT_PRIORITY>;
			interrupt-names = "ccmpa", "ccmpb", "cmpc", "cmpd", "cmpe", "cmpf",
					  "adtrga", "adtrgb", "ovf", "unf";
			interrupt-parent = <&gic>;
			clocks = <&cpg CPG_MOD 30>, <&cpg CPG_CORE R7S9210_CLK_P1C>;
			#pwm-cells = <3>;
			channel-id = <2>;
			status = "disabled";
		};

		gpt32e3: gpt32e3@e8043300 {
			compatible = "renesas,rza2m-pwm";
			reg = <0xe8043300 0xa4>, <0xe804381c 0x4>;
			reg-names = "GPT32E", "GTESR";
			interrupts = <GIC_SPI 146 IRQ_TYPE_EDGE IRQ_DEFAULT_PRIORITY>,
				     <GIC_SPI 147 IRQ_TYPE_EDGE IRQ_DEFAULT_PRIORITY>,
				     <GIC_SPI 148 IRQ_TYPE_EDGE IRQ_DEFAULT_PRIORITY>,
				     <GIC_SPI 149 IRQ_TYPE_EDGE IRQ_DEFAULT_PRIORITY>,
				     <GIC_SPI 153 IRQ_TYPE_EDGE IRQ_DEFAULT_PRIORITY>,
				     <GIC_SPI 154 IRQ_TYPE_EDGE IRQ_DEFAULT_PRIORITY>,
				     <GIC_SPI 155 IRQ_TYPE_EDGE IRQ_DEFAULT_PRIORITY>,
				     <GIC_SPI 156 IRQ_TYPE_EDGE IRQ_DEFAULT_PRIORITY>,
				     <GIC_SPI 157 IRQ_TYPE_EDGE IRQ_DEFAULT_PRIORITY>,
				     <GIC_SPI 158 IRQ_TYPE_EDGE IRQ_DEFAULT_PRIORITY>;
			interrupt-names = "ccmpa", "ccmpb", "cmpc", "cmpd", "cmpe", "cmpf",
					  "adtrga", "adtrgb", "ovf", "unf";
			interrupt-parent = <&gic>;
			clocks = <&cpg CPG_MOD 30>, <&cpg CPG_CORE R7S9210_CLK_P1C>;
			#pwm-cells = <3>;
			channel-id = <3>;
			status = "disabled";
		};

		gpt32e4: gpt32e4@e8043400 {
			compatible = "renesas,rza2m-pwm";
			reg = <0xe8043400 0xa4>, <0xe8043820 0x4>;
			reg-names = "GPT32E", "GTESR";
			interrupts = <GIC_SPI 159 IRQ_TYPE_EDGE IRQ_DEFAULT_PRIORITY>,
				     <GIC_SPI 160 IRQ_TYPE_EDGE IRQ_DEFAULT_PRIORITY>,
				     <GIC_SPI 161 IRQ_TYPE_EDGE IRQ_DEFAULT_PRIORITY>,
				     <GIC_SPI 162 IRQ_TYPE_EDGE IRQ_DEFAULT_PRIORITY>,
				     <GIC_SPI 166 IRQ_TYPE_EDGE IRQ_DEFAULT_PRIORITY>,
				     <GIC_SPI 167 IRQ_TYPE_EDGE IRQ_DEFAULT_PRIORITY>,
				     <GIC_SPI 168 IRQ_TYPE_EDGE IRQ_DEFAULT_PRIORITY>,
				     <GIC_SPI 169 IRQ_TYPE_EDGE IRQ_DEFAULT_PRIORITY>,
				     <GIC_SPI 170 IRQ_TYPE_EDGE IRQ_DEFAULT_PRIORITY>,
				     <GIC_SPI 171 IRQ_TYPE_EDGE IRQ_DEFAULT_PRIORITY>;
			interrupt-names = "ccmpa", "ccmpb", "cmpc", "cmpd", "cmpe", "cmpf",
					  "adtrga", "adtrgb", "ovf", "unf";
			interrupt-parent = <&gic>;
			clocks = <&cpg CPG_MOD 30>, <&cpg CPG_CORE R7S9210_CLK_P1C>;
			#pwm-cells = <3>;
			channel-id = <4>;
			status = "disabled";
		};

		gpt32e5: gpt32e5@e8043500 {
			compatible = "renesas,rza2m-pwm";
			reg = <0xe8043500 0xa4>, <0xe8043824 0x4>;
			reg-names = "GPT32E", "GTESR";
			interrupts = <GIC_SPI 172 IRQ_TYPE_EDGE IRQ_DEFAULT_PRIORITY>,
				     <GIC_SPI 173 IRQ_TYPE_EDGE IRQ_DEFAULT_PRIORITY>,
				     <GIC_SPI 174 IRQ_TYPE_EDGE IRQ_DEFAULT_PRIORITY>,
				     <GIC_SPI 175 IRQ_TYPE_EDGE IRQ_DEFAULT_PRIORITY>,
				     <GIC_SPI 179 IRQ_TYPE_EDGE IRQ_DEFAULT_PRIORITY>,
				     <GIC_SPI 180 IRQ_TYPE_EDGE IRQ_DEFAULT_PRIORITY>,
				     <GIC_SPI 181 IRQ_TYPE_EDGE IRQ_DEFAULT_PRIORITY>,
				     <GIC_SPI 182 IRQ_TYPE_EDGE IRQ_DEFAULT_PRIORITY>,
				     <GIC_SPI 183 IRQ_TYPE_EDGE IRQ_DEFAULT_PRIORITY>,
				     <GIC_SPI 184 IRQ_TYPE_EDGE IRQ_DEFAULT_PRIORITY>;
			interrupt-names = "ccmpa", "ccmpb", "cmpc", "cmpd", "cmpe", "cmpf",
					  "adtrga", "adtrgb", "ovf", "unf";
			interrupt-parent = <&gic>;
			clocks = <&cpg CPG_MOD 30>, <&cpg CPG_CORE R7S9210_CLK_P1C>;
			#pwm-cells = <3>;
			channel-id = <5>;
			status = "disabled";
		};

		gpt32e6: gpt32e6@e8043600 {
			compatible = "renesas,rza2m-pwm";
			reg = <0xe8043600 0xa4>, <0xe8043828 0x4>;
			reg-names = "GPT32E", "GTESR";
			interrupts = <GIC_SPI 185 IRQ_TYPE_EDGE IRQ_DEFAULT_PRIORITY>,
				     <GIC_SPI 186 IRQ_TYPE_EDGE IRQ_DEFAULT_PRIORITY>,
				     <GIC_SPI 187 IRQ_TYPE_EDGE IRQ_DEFAULT_PRIORITY>,
				     <GIC_SPI 188 IRQ_TYPE_EDGE IRQ_DEFAULT_PRIORITY>,
				     <GIC_SPI 192 IRQ_TYPE_EDGE IRQ_DEFAULT_PRIORITY>,
				     <GIC_SPI 193 IRQ_TYPE_EDGE IRQ_DEFAULT_PRIORITY>,
				     <GIC_SPI 194 IRQ_TYPE_EDGE IRQ_DEFAULT_PRIORITY>,
				     <GIC_SPI 195 IRQ_TYPE_EDGE IRQ_DEFAULT_PRIORITY>,
				     <GIC_SPI 196 IRQ_TYPE_EDGE IRQ_DEFAULT_PRIORITY>,
				     <GIC_SPI 197 IRQ_TYPE_EDGE IRQ_DEFAULT_PRIORITY>;
			interrupt-names = "ccmpa", "ccmpb", "cmpc", "cmpd", "cmpe", "cmpf",
					  "adtrga", "adtrgb", "ovf", "unf";
			interrupt-parent = <&gic>;
			clocks = <&cpg CPG_MOD 30>, <&cpg CPG_CORE R7S9210_CLK_P1C>;
			#pwm-cells = <3>;
			channel-id = <6>;
			status = "disabled";
		};

		gpt32e7: gpt32e7@e8043700 {
			compatible = "renesas,rza2m-pwm";
			reg = <0xe8043700 0xa4>, <0xe804382c 0x4>;
			reg-names = "GPT32E", "GTESR";
			interrupts = <GIC_SPI 198 IRQ_TYPE_EDGE IRQ_DEFAULT_PRIORITY>,
				     <GIC_SPI 199 IRQ_TYPE_EDGE IRQ_DEFAULT_PRIORITY>,
				     <GIC_SPI 200 IRQ_TYPE_EDGE IRQ_DEFAULT_PRIORITY>,
				     <GIC_SPI 201 IRQ_TYPE_EDGE IRQ_DEFAULT_PRIORITY>,
				     <GIC_SPI 205 IRQ_TYPE_EDGE IRQ_DEFAULT_PRIORITY>,
				     <GIC_SPI 206 IRQ_TYPE_EDGE IRQ_DEFAULT_PRIORITY>,
				     <GIC_SPI 207 IRQ_TYPE_EDGE IRQ_DEFAULT_PRIORITY>,
				     <GIC_SPI 208 IRQ_TYPE_EDGE IRQ_DEFAULT_PRIORITY>,
				     <GIC_SPI 209 IRQ_TYPE_EDGE IRQ_DEFAULT_PRIORITY>,
				     <GIC_SPI 210 IRQ_TYPE_EDGE IRQ_DEFAULT_PRIORITY>;
			interrupt-names = "ccmpa", "ccmpb", "cmpc", "cmpd", "cmpe", "cmpf",
					  "adtrga", "adtrgb", "ovf", "unf";
			interrupt-parent = <&gic>;
			clocks = <&cpg CPG_MOD 30>, <&cpg CPG_CORE R7S9210_CLK_P1C>;
			#pwm-cells = <3>;
			channel-id = <7>;
			status = "disabled";
		};

		/* Multi-function timers (MTU) */
		mtu0: mtu0@e8041300 {
			compatible = "renesas,rza2m-mtu";
			reg = <0xe8041300 0x29>, <0xe8041290 0x1>,
			      <0xe8041299 0x1>, <0xe804120a 0x78>, <0xe8041a0a 0x7b>;
			reg-names = "mtu", "noise_flt_cr",
				    "noise_flt_cr_cmn", "mtu_cmn_a", "mtu_cmn_b";
			interrupts = <GIC_SPI 63 IRQ_TYPE_EDGE IRQ_DEFAULT_PRIORITY>,
				     <GIC_SPI 64 IRQ_TYPE_EDGE IRQ_DEFAULT_PRIORITY>,
				     <GIC_SPI 65 IRQ_TYPE_EDGE IRQ_DEFAULT_PRIORITY>,
				     <GIC_SPI 66 IRQ_TYPE_EDGE IRQ_DEFAULT_PRIORITY>,
				     <GIC_SPI 67 IRQ_TYPE_EDGE IRQ_DEFAULT_PRIORITY>,
				     <GIC_SPI 68 IRQ_TYPE_EDGE IRQ_DEFAULT_PRIORITY>,
				     <GIC_SPI 69 IRQ_TYPE_EDGE IRQ_DEFAULT_PRIORITY>;
			interrupt-names = "tgia", "tgib", "tgic", "tgid", "tciv", "tgie", "tgif";
			interrupt-parent = <&gic>;
			clocks = <&cpg CPG_MOD 33>, <&cpg CPG_CORE R7S9210_CLK_P1C>;
			#pwm-cells = <3>;
			channel-id = <0>;
			status = "disabled";
		};

		mtu1: mtu1@e8041380 {
			compatible = "renesas,rza2m-mtu";
			reg = <0xe8041380 0x2C>, <0xe8041291 0x1>,
			      <0xe8041299 0x1>, <0xe804120a 0x78>, <0xe8041a0a 0x7b>;
			reg-names = "mtu", "noise_flt_cr",
				    "noise_flt_cr_cmn", "mtu_cmn_a", "mtu_cmn_b";
			interrupts = <GIC_SPI 70 IRQ_TYPE_EDGE IRQ_DEFAULT_PRIORITY>,
				     <GIC_SPI 71 IRQ_TYPE_EDGE IRQ_DEFAULT_PRIORITY>,
				     <GIC_SPI 72 IRQ_TYPE_EDGE IRQ_DEFAULT_PRIORITY>,
				     <GIC_SPI 73 IRQ_TYPE_EDGE IRQ_DEFAULT_PRIORITY>;
			interrupt-names = "tgia", "tgib", "tciv", "tciu";
			interrupt-parent = <&gic>;
			clocks = <&cpg CPG_MOD 33>, <&cpg CPG_CORE R7S9210_CLK_P1C>;
			#pwm-cells = <3>;
			channel-id = <1>;
			status = "disabled";
		};

		mtu2: mtu2@e8041400 {
			compatible = "renesas,rza2m-mtu";
			reg = <0xe8041400 0xd>, <0xe8041292 0x1>,
			      <0xe8041299 0x1>, <0xe804120a 0x78>, <0xe8041a0a 0x7b>;
			reg-names = "mtu", "noise_flt_cr",
				    "noise_flt_cr_cmn", "mtu_cmn_a", "mtu_cmn_b";
			interrupts = <GIC_SPI 74 IRQ_TYPE_EDGE IRQ_DEFAULT_PRIORITY>,
				     <GIC_SPI 75 IRQ_TYPE_EDGE IRQ_DEFAULT_PRIORITY>,
				     <GIC_SPI 76 IRQ_TYPE_EDGE IRQ_DEFAULT_PRIORITY>,
				     <GIC_SPI 77 IRQ_TYPE_EDGE IRQ_DEFAULT_PRIORITY>;
			interrupt-names = "tgia", "tgib", "tciv", "tciu";
			interrupt-parent = <&gic>;
			clocks = <&cpg CPG_MOD 33>, <&cpg CPG_CORE R7S9210_CLK_P1C>;
			#pwm-cells = <3>;
			channel-id = <2>;
			status = "disabled";
		};

		mtu3: mtu3@e8041200 {
			compatible = "renesas,rza2m-mtu";
			reg = <0xe8041200 0x39>, <0xe8041293 0x1>,
			      <0xe8041299 0x1>, <0xe804120a 0x78>, <0xe8041a0a 0x7b>;
			reg-names = "mtu", "noise_flt_cr",
				    "noise_flt_cr_cmn", "mtu_cmn_a", "mtu_cmn_b";
			interrupts = <GIC_SPI 78 IRQ_TYPE_EDGE IRQ_DEFAULT_PRIORITY>,
				     <GIC_SPI 79 IRQ_TYPE_EDGE IRQ_DEFAULT_PRIORITY>,
				     <GIC_SPI 80 IRQ_TYPE_EDGE IRQ_DEFAULT_PRIORITY>,
				     <GIC_SPI 81 IRQ_TYPE_EDGE IRQ_DEFAULT_PRIORITY>,
				     <GIC_SPI 82 IRQ_TYPE_EDGE IRQ_DEFAULT_PRIORITY>;
			interrupt-names = "tgia", "tgib", "tgic", "tgid", "tciv";
			interrupt-parent = <&gic>;
			clocks = <&cpg CPG_MOD 33>, <&cpg CPG_CORE R7S9210_CLK_P1C>;
			#pwm-cells = <3>;
			channel-id = <3>;
			status = "disabled";
		};

		mtu4: mtu4@e8041201 {
			compatible = "renesas,rza2m-mtu";
			reg = <0xe8041201 0x77>, <0xe8041294 0x1>,
			      <0xe8041299 0x1>, <0xe804120a 0x78>, <0xe8041a0a 0x7b>;
			reg-names = "mtu", "noise_flt_cr",
				    "noise_flt_cr_cmn", "mtu_cmn_a", "mtu_cmn_b";
			interrupts = <GIC_SPI 83 IRQ_TYPE_EDGE IRQ_DEFAULT_PRIORITY>,
				     <GIC_SPI 84 IRQ_TYPE_EDGE IRQ_DEFAULT_PRIORITY>,
				     <GIC_SPI 85 IRQ_TYPE_EDGE IRQ_DEFAULT_PRIORITY>,
				     <GIC_SPI 86 IRQ_TYPE_EDGE IRQ_DEFAULT_PRIORITY>,
				     <GIC_SPI 87 IRQ_TYPE_EDGE IRQ_DEFAULT_PRIORITY>;
			interrupt-names = "tgia", "tgib", "tgic", "tgid", "tciv";
			interrupt-parent = <&gic>;
			clocks = <&cpg CPG_MOD 33>, <&cpg CPG_CORE R7S9210_CLK_P1C>;
			#pwm-cells = <3>;
			channel-id = <4>;
			status = "disabled";
		};

		mtu5: mtu5@e8041c80 {
			compatible = "renesas,rza2m-mtu";
			reg = <0xe8041c80 0x37>, <0xe8041a95 0x1>,
			      <0xe8041299 0x1>, <0xe804120a 0x78>, <0xe8041a0a 0x7b>;
			reg-names = "mtu", "noise_flt_cr",
				    "noise_flt_cr_cmn", "mtu_cmn_a", "mtu_cmn_b";
			interrupts = <GIC_SPI 88 IRQ_TYPE_EDGE IRQ_DEFAULT_PRIORITY>,
				     <GIC_SPI 89 IRQ_TYPE_EDGE IRQ_DEFAULT_PRIORITY>,
				     <GIC_SPI 90 IRQ_TYPE_EDGE IRQ_DEFAULT_PRIORITY>;
			interrupt-names = "tgiu", "tgiv", "tgiw";
			interrupt-parent = <&gic>;
			clocks = <&cpg CPG_MOD 33>, <&cpg CPG_CORE R7S9210_CLK_P1C>;
			#pwm-cells = <3>;
			channel-id = <5>;
			status = "disabled";
		};

		mtu6: mtu6@e8041a00 {
			compatible = "renesas,rza2m-mtu";
			reg = <0xe8041a00 0x39>, <0xe8041a93 0x1>,
			      <0xe8041299 0x1>, <0xe804120a 0x78>, <0xe8041a0a 0x7b>;
			reg-names = "mtu", "noise_flt_cr",
				    "noise_flt_cr_cmn", "mtu_cmn_a", "mtu_cmn_b";
			interrupts = <GIC_SPI 91 IRQ_TYPE_EDGE IRQ_DEFAULT_PRIORITY>,
				     <GIC_SPI 92 IRQ_TYPE_EDGE IRQ_DEFAULT_PRIORITY>,
				     <GIC_SPI 93 IRQ_TYPE_EDGE IRQ_DEFAULT_PRIORITY>,
				     <GIC_SPI 94 IRQ_TYPE_EDGE IRQ_DEFAULT_PRIORITY>,
				     <GIC_SPI 95 IRQ_TYPE_EDGE IRQ_DEFAULT_PRIORITY>;
			interrupt-names = "tgia", "tgib", "tgic", "tgid", "tciv";
			interrupt-parent = <&gic>;
			clocks = <&cpg CPG_MOD 33>, <&cpg CPG_CORE R7S9210_CLK_P1C>;
			#pwm-cells = <3>;
			channel-id = <6>;
			status = "disabled";
		};

		mtu7: mtu7@e8041a01 {
			compatible = "renesas,rza2m-mtu";
			reg = <0xe8041a01 0x77>, <0xe8041a94 0x1>,
			      <0xe8041299 0x1>, <0xe804120a 0x78>, <0xe8041a0a 0x7b>;
			reg-names = "mtu", "noise_flt_cr",
				    "noise_flt_cr_cmn", "mtu_cmn_a", "mtu_cmn_b";
			interrupts = <GIC_SPI 96  IRQ_TYPE_EDGE IRQ_DEFAULT_PRIORITY>,
				     <GIC_SPI 97  IRQ_TYPE_EDGE IRQ_DEFAULT_PRIORITY>,
				     <GIC_SPI 98  IRQ_TYPE_EDGE IRQ_DEFAULT_PRIORITY>,
				     <GIC_SPI 99  IRQ_TYPE_EDGE IRQ_DEFAULT_PRIORITY>,
				     <GIC_SPI 100 IRQ_TYPE_EDGE IRQ_DEFAULT_PRIORITY>;
			interrupt-names = "tgia", "tgib", "tgic", "tgid", "tciv";
			interrupt-parent = <&gic>;
			clocks = <&cpg CPG_MOD 33>, <&cpg CPG_CORE R7S9210_CLK_P1C>;
			#pwm-cells = <3>;
			channel-id = <7>;
			status = "disabled";
		};

		mtu8: mtu8@e8041600 {
			compatible = "renesas,rza2m-mtu";
			reg = <0xe8041600 0x1C>, <0xe8041298 0x1>,
			      <0xe8041299 0x1>, <0xe804120a 0x78>, <0xe8041a0a 0x7b>;
			reg-names = "mtu", "noise_flt_cr",
				    "noise_flt_cr_cmn", "mtu_cmn_a", "mtu_cmn_b";
			interrupts = <GIC_SPI 101 IRQ_TYPE_EDGE IRQ_DEFAULT_PRIORITY>,
				     <GIC_SPI 102 IRQ_TYPE_EDGE IRQ_DEFAULT_PRIORITY>,
				     <GIC_SPI 103 IRQ_TYPE_EDGE IRQ_DEFAULT_PRIORITY>,
				     <GIC_SPI 104 IRQ_TYPE_EDGE IRQ_DEFAULT_PRIORITY>,
				     <GIC_SPI 105 IRQ_TYPE_EDGE IRQ_DEFAULT_PRIORITY>;
			interrupt-names = "tgia", "tgib", "tgic", "tgid", "tciv";
			interrupt-parent = <&gic>;
			clocks = <&cpg CPG_MOD 33>, <&cpg CPG_CORE R7S9210_CLK_P1C>;
			#pwm-cells = <3>;
			channel-id = <8>;
			status = "disabled";
		};

		sci0: serial@e800b000 {
			compatible = "renesas,rza2m-sci";
			reg = <0xe800b000 0x14>;
			interrupt-parent = <&gic>;
			interrupts = <GIC_SPI 333 IRQ_TYPE_LEVEL IRQ_DEFAULT_PRIORITY>,
				     <GIC_SPI 334 IRQ_TYPE_EDGE IRQ_DEFAULT_PRIORITY>,
				     <GIC_SPI 335 IRQ_TYPE_EDGE IRQ_DEFAULT_PRIORITY>,
				     <GIC_SPI 336 IRQ_TYPE_LEVEL IRQ_DEFAULT_PRIORITY>;
			interrupt-names = "eri", "rxi", "txi", "tei";
			clocks = <&cpg CPG_MOD 42>, <&cpg CPG_CORE R7S9210_CLK_P1C>;
			clock-names = "fck", "bus";
			status = "disabled";
		};

		sci1: serial@e800b800 {
			compatible = "renesas,rza2m-sci";
			reg = <0xe800b800 0x14>;
			interrupt-parent = <&gic>;
			interrupts = <GIC_SPI 337 IRQ_TYPE_LEVEL IRQ_DEFAULT_PRIORITY>,
				     <GIC_SPI 338 IRQ_TYPE_EDGE IRQ_DEFAULT_PRIORITY>,
				     <GIC_SPI 339 IRQ_TYPE_EDGE IRQ_DEFAULT_PRIORITY>,
				     <GIC_SPI 340 IRQ_TYPE_LEVEL IRQ_DEFAULT_PRIORITY>;
			interrupt-names = "eri", "rxi", "txi", "tei";
			clocks = <&cpg CPG_MOD 41>, <&cpg CPG_CORE R7S9210_CLK_P1C>;
			clock-names = "fck", "bus";
			status = "disabled";
		};

		ether0: ethernet@e8204000 {
			compatible = "renesas,ether-r7s9210";
			reg = <0xe8204000 0x200>;
			interrupts = <GIC_SPI 341 IRQ_TYPE_LEVEL IRQ_DEFAULT_PRIORITY>;
			clocks = <&cpg CPG_MOD 65>, <&cpg CPG_MOD 62>;

			phy-mode = "rmii";
			status = "disabled";
		};

		ether1: ethernet@e8204200 {
			compatible = "renesas,ether-r7s9210";
			reg = <0xe8204200 0x200>;
			interrupts = <GIC_SPI 342 IRQ_TYPE_LEVEL IRQ_DEFAULT_PRIORITY>;
			clocks = <&cpg CPG_MOD 64>, <&cpg CPG_MOD 62>;

			phy-mode = "rmii";
			status = "disabled";
		};

		spi0: spi@e800c800 {
			compatible = "renesas,rspi-r7s9210", "renesas,rspi-rz";
			reg = <0xe800c800 0x24>;
			interrupts = <GIC_SPI 312 IRQ_TYPE_LEVEL IRQ_DEFAULT_PRIORITY>,
				     <GIC_SPI 313 IRQ_TYPE_LEVEL IRQ_DEFAULT_PRIORITY>,
				     <GIC_SPI 314 IRQ_TYPE_LEVEL IRQ_DEFAULT_PRIORITY>;
			interrupt-names = "error", "rx", "tx";
			clocks = <&cpg CPG_MOD 97>;
			num-cs = <1>;
			#address-cells = <1>;
			#size-cells = <0>;
			status = "disabled";
		};

		spi1: spi@e800d000 {
			compatible = "renesas,rspi-r7s9210", "renesas,rspi-rz";
			reg = <0xe800d000 0x24>;
			interrupts = <GIC_SPI 315 IRQ_TYPE_LEVEL IRQ_DEFAULT_PRIORITY>,
				     <GIC_SPI 316 IRQ_TYPE_LEVEL IRQ_DEFAULT_PRIORITY>,
				     <GIC_SPI 317 IRQ_TYPE_LEVEL IRQ_DEFAULT_PRIORITY>;
			interrupt-names = "error", "rx", "tx";
			clocks = <&cpg CPG_MOD 96>;
			num-cs = <1>;
			#address-cells = <1>;
			#size-cells = <0>;
			status = "disabled";
		};

		spi2: spi@e800d800 {
			compatible = "renesas,rspi-r7s9210", "renesas,rspi-rz";
			reg = <0xe800d800 0x24>;
			interrupts = <GIC_SPI 318 IRQ_TYPE_LEVEL IRQ_DEFAULT_PRIORITY>,
				     <GIC_SPI 319 IRQ_TYPE_LEVEL IRQ_DEFAULT_PRIORITY>,
				     <GIC_SPI 320 IRQ_TYPE_LEVEL IRQ_DEFAULT_PRIORITY>;
			interrupt-names = "error", "rx", "tx";
			clocks = <&cpg CPG_MOD 95>;
			num-cs = <1>;
			#address-cells = <1>;
			#size-cells = <0>;
			status = "disabled";
		};

		usbd0: usbd0@e8219000 {
			compatible = "renesas,rza2-usbd";
			reg = <0xe8219000 0x1000>, <0xe8218000 0x1000>;
			reg-names = "dev_reg", "host_reg";
			num-bidir-endpoints = <8>;
			maximum-speed = "high-speed";
			clocks = <&cpg CPG_MOD 61>, <&usb_x1_clk>;
			clock-names = "default", "usb_x1";
			interrupts = <GIC_SPI 31 IRQ_TYPE_LEVEL IRQ_DEFAULT_PRIORITY>,
				     <GIC_SPI 32 IRQ_TYPE_LEVEL IRQ_DEFAULT_PRIORITY>,
				     <GIC_SPI 33 IRQ_TYPE_LEVEL IRQ_DEFAULT_PRIORITY>,
				     <GIC_SPI 34 IRQ_TYPE_LEVEL IRQ_DEFAULT_PRIORITY>,
				     <GIC_SPI 35 IRQ_TYPE_LEVEL IRQ_DEFAULT_PRIORITY>;
			interrupt-names = "usbh", "usbf", "dma0", "dma1", "dmaerr";
		};

		usbd1: usbd@e821b000 {
			compatible = "renesas,rza2-usbd";
			reg = <0xe821b000 0x1000>, <0xe821a000 0x1000>;
			reg-names = "dev_reg", "host_reg";
			num-bidir-endpoints = <8>;
			maximum-speed = "high-speed";
			clocks = <&cpg CPG_MOD 60>, <&usb_x1_clk>;
			clock-names = "default", "usb_x1";
			interrupts = <GIC_SPI 36 IRQ_TYPE_LEVEL IRQ_DEFAULT_PRIORITY>,
				     <GIC_SPI 37 IRQ_TYPE_LEVEL IRQ_DEFAULT_PRIORITY>,
				     <GIC_SPI 38 IRQ_TYPE_LEVEL IRQ_DEFAULT_PRIORITY>,
				     <GIC_SPI 39 IRQ_TYPE_LEVEL IRQ_DEFAULT_PRIORITY>,
				     <GIC_SPI 40 IRQ_TYPE_LEVEL IRQ_DEFAULT_PRIORITY>;
			interrupt-names = "usbh", "usbf", "dma0", "dma1", "dmaerr";
		};
	};

		/* I2S Interfaces */
		ssif0: ssif@e8048000 {
			compatible = "renesas,ssif2", "renesas,rza2m-ssif2";
			#address-cells = <1>;
			#size-cells = <0>;
			reg = <0xe8048000 0x30>;
			interrupt-parent = <&gic>;
			interrupts = <GIC_SPI 220 IRQ_TYPE_LEVEL IRQ_DEFAULT_PRIORITY>,
				     <GIC_SPI 221 IRQ_TYPE_EDGE IRQ_DEFAULT_PRIORITY>,
				     <GIC_SPI 222 IRQ_TYPE_EDGE IRQ_DEFAULT_PRIORITY>;
			interrupt-names = "int_req", "dma_tx", "dma_rx";
			dmas = <&dma0 0 DMA_RS_INT_SSIF_DMA_RX_0 0>,
			       <&dma0 1 DMA_RS_INT_SSIF_DMA_TX_0 0>;
			dma-names = "rx", "tx";
			clocks = <&cpg CPG_MOD 73>, <&cpg CPG_CORE R7S9210_CLK_P1>, <&audio_clk>;
			clock-names = "fck", "bus", "audio";
			status = "disabled";
		};

		ssif1: ssif@e8048800 {
			compatible = "renesas,ssif2", "renesas,rza2m-ssif2";
			#address-cells = <1>;
			#size-cells = <0>;
			reg = <0xe8048800 0x30>;
			interrupt-parent = <&gic>;
			interrupts = <GIC_SPI 223 IRQ_TYPE_LEVEL IRQ_DEFAULT_PRIORITY>,
				     <GIC_SPI 224 IRQ_TYPE_EDGE IRQ_DEFAULT_PRIORITY>,
				     <GIC_SPI 225 IRQ_TYPE_EDGE IRQ_DEFAULT_PRIORITY>;
			interrupt-names = "int_req", "dma_tx", "dma_rx";
			dmas = <&dma0 0 DMA_RS_INT_SSIF_DMA_RX_1 0>,
			       <&dma0 1 DMA_RS_INT_SSIF_DMA_TX_1 0>;
			dma-names = "rx", "tx";
			clocks = <&cpg CPG_MOD 72>, <&cpg CPG_CORE R7S9210_CLK_P1>, <&audio_clk>;
			clock-names = "fck", "bus", "audio";
			status = "disabled";
		};

		ssif2: ssif@e8049000 {
			compatible = "renesas,ssif2", "renesas,rza2m-ssif2";
			#address-cells = <1>;
			#size-cells = <0>;
			reg = <0xe8049000 0x30>;
			interrupt-parent = <&gic>;
			interrupts = <GIC_SPI 226 IRQ_TYPE_LEVEL IRQ_DEFAULT_PRIORITY>,
				     <GIC_SPI 227 IRQ_TYPE_EDGE IRQ_DEFAULT_PRIORITY>;
			interrupt-names = "int_req", "dma_rt";
			dmas = <&dma0 0 DMA_RS_INT_SSIF_DMA_RX_2 0>,
			       <&dma0 1 DMA_RS_INT_SSIF_DMA_TX_2 0>;
			dma-names = "rx", "tx";
			clocks = <&cpg CPG_MOD 71>, <&cpg CPG_CORE R7S9210_CLK_P1>, <&audio_clk>;
			clock-names = "fck", "bus", "audio";
			status = "disabled";
		};

		ssif3: ssif@e8049800 {
			compatible = "renesas,ssif2", "renesas,rza2m-ssif2";
			#address-cells = <1>;
			#size-cells = <0>;
			reg = <0xe8049800 0x30>;
			interrupt-parent = <&gic>;
			interrupts = <GIC_SPI 228 IRQ_TYPE_LEVEL IRQ_DEFAULT_PRIORITY>,
				     <GIC_SPI 229 IRQ_TYPE_EDGE IRQ_DEFAULT_PRIORITY>,
				     <GIC_SPI 230 IRQ_TYPE_EDGE IRQ_DEFAULT_PRIORITY>;
			interrupt-names = "int_req", "dma_tx", "dma_rx";
			dmas = <&dma0 0 DMA_RS_INT_SSIF_DMA_RX_3 0>,
			       <&dma0 1 DMA_RS_INT_SSIF_DMA_TX_3 0>;
			dma-names = "rx", "tx";
			clocks = <&cpg CPG_MOD 70>, <&cpg CPG_CORE R7S9210_CLK_P1>, <&audio_clk>;
			clock-names = "fck", "bus", "audio";
			status = "disabled";
		};
};
